# ISS_TCTRL register map
Vendor: Texas Instruments
Peripheral module from a debugger description file (folder omap5430_ES2_PUBLIC).
Registers are 32-bit, access per field, reset 0x0 unless marked. A register's access mark holds for its fields unless they carry their own. Offsets are as the file gives them; lines under a group give offsets from that group; [hi:lo] are bit positions; {n}, {i} and the like mark numbered series; 'fields as' and 'values as' point back to an identical list; <NAME> marks a mode.

## ISS_TCTRL
0x00 TCTRL_REVISION ro reset not defined — IP Revision Identifier (X.Y.R) Used by software to track features, bugs, and compatibility
  [31:0] REVISION — IP revision
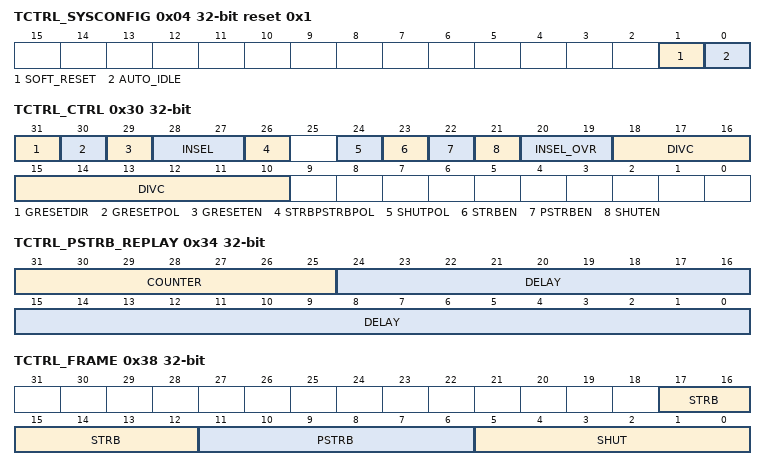
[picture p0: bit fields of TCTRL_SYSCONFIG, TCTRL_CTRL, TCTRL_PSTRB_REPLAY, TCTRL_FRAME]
0x04 TCTRL_SYSCONFIG reset 0x1 — OCP-SOCKET SYSTEM CONFIGURATION REGISTER
  [1] SOFT_RESET rw — Software reset. Set the bit to 1 to trigger the module reset. The bit is automatically reset be the hardware. During reads return 0.
    0=Normal mode; 1=Reset (The module is reset.)
  [0] AUTO_IDLE rw — Internal OCP and functional clock gating strategy
    0=Free (OCP and functional clocks are free-running); 1=Gated (Automatic clock gating strategy is applied, based on the OCP interface activity for interface clock and on the functional activity for functional clocks.)
0x08 TCTRL_SYSSTATUS ro — OCP-SOCKET SYSTEM STATUS REGISTER
  [0] RESET_DONE — Internal reset monitoring
    1=Completed (Reset completed.); 0=Ongoing (Internal module reset is ongoing.)
0x10 TCTRL_STRB_LENGTH — TIMING CONTROL - STROBE LENGTH REGISTER This register is used by the TIMING CTRL module to generate the STROBE signal.
  [23:0] LENGTH rw — Sets the length of the CAM_STROBE signal assertion in cycles of the CNTCLK clock. The CNTCLK frequency is generated with theTCTRL_CTRL[18:10] DIVC bit field. After signal assertion, the TCTRL_CTRL.STRBEN bit is automatically cleared. The possible values are 0 to 2-1 cycles.
0x14 TCTRL_PSTRB_LENGTH — TIMING CONTROL - PRESTROBE LENGTH REGISTER This register is used by the TIMING CTRL module to generate the PRESTROBE signal.
  [23:0] LENGTH rw — Sets the length of the CAM_PRESTROBE signal assertion in cycles of the CNTCLK clock. The CNTCLK frequency is generated with theTCTRL_CTRL.DIVC bit field. After signal assertion, the TCTRL_CTRL[22] PSTRBEN bit is automatically cleared. The possible values are 0 to 2-1 cycles.
0x18 TCTRL_SHUT_LENGTH — TIMING CONTROL - SHUTTER LENGTH REGISTER This register is used by the TIMING CTRL module to generate the CAM_SHUTTER signal.
  [23:0] LENGTH rw — Sets the length of the CAM_SHUTTER signal assertion in cycles of the CNTCLK clock. The CNTCLK frequency is generated with theTCTRL_CTRL.DIVC bit field. After signal assertion, the TCTRL_CTRL.SHUTEN bit is automatically cleared. The possible values are 0 to 2-1 cycles.
0x1C TCTRL_GRESET_LENGTH — TIMING CONTROL - GLOBAL SHUTTER LENGTH REGISTER This register is used by the TIMING CTRL module to generate the CAM_GLOBALRESET signal.
  [23:0] LENGTH rw — Sets the length of the CAM_GLOBALRESET signal assertion in cycles of the CNTCLK clock. The CNTCLK frequency is generated with the TCTRL_CTRL.DIVC bit field. After signal assertion, the TCTRL_CTRL.GRESETEN bit is automatically cleared. The possible values are 0 to 2-1 cycles. The polarity of the CAM_GLOBALRESET signal is set by the TCTRL_CTRL.GRESETPOL bit.
0x20 TCTRL_STRB_DELAY — TIMING CONTROL - STROBE DELAY REGISTER This register is used by the TIMING CTRL module to generate the STROBE signal.
  [24:0] DELAY rw — Sets the delay for the CAM_STROBE signal assertion in cycles of the CNTCLK clock. The CNTCLK frequency is generated with theTCTRL_CTRL.DIVC bit field. The possible values are 0 to 2-1 cycles.
0x24 TCTRL_PSTRB_DELAY — TIMING CONTROL - PRE STROBE DELAY REGISTER This register is used by the TIMING CTRL module to generate the PRESTROBE signal.
  [24:0] DELAY rw — Sets the delay for the PRESTROBE signal assertion in cycles of the CNTCLK clock. The CNTCLK frequency is generated with theTCTRL_CTRL.DIVC bit field. The possible values are 0 to 2-1 cycles.
0x28 TCTRL_SHUT_DELAY — TIMING CONTROL - SHUTTER DELAY REGISTER This register is used by the TIMING CTRL module to generate the CAM_SHUTTER signal.
  [24:0] DELAY rw — Sets the delay for the CAM_SHUTTER signal assertion in cycles of the CNTCLK clock. The CNTCLK frequency is generated with theTCTRL_CTRL.DIVC bit field. The possible values are 0 to 2-1 cycles.
0x30 TCTRL_CTRL — TIMING CONTROL - CONTROL REGISTER
  [31] GRESETDIR rw — Sets the direction of the CAM_GLOBAL_RESET signal. 0x0: INPUT – CAM_GLOBALRESET is an input to the TIMING CONTROL module. The CAM_GLOBALRESET is externally generated. 0x1: OUTPUT – CAM_GLOBALRESET is an output of the TIMING CONTROL module. CAM_GLOBALRESET is internally generated. If GRESETEN is set to 1, the internally generated CAM_GLOBALRESET will trigger the generation of the PRESTROBE, STROBE and SHUTTER signals. The frame counters are ignored.
  [30] GRESETPOL rw — Sets the polarity of the global reset signal: CAM_GLOBALRESET. It applies whatever the direction of the CAM_GLOBALRESET signal: input or output. 0x0: active high 0x1: active low
  [29] GRESETEN rw — Triggers the generation of the CAM_GLOBALRESET signal. The signal is asserted immediately. If enabled, the CAM_GLOBALRESET signal will be asserted forTCTRL_GRESET_LENGTH cycles. After the signal assertion, the enable bit is automatically cleared to 0. The polarity of the CAM_GLOBALRESET signal is set with TCTRL_CTRL.GRESETPOL. Enabling this bit triggers the generation of the CAM_SHUTTER and CAM_STROBE signals (if previously enabled). The frame counters must be set to 0 when this bit is set to 1 and GRESETDIR is set a OUTPUT.
  [28:27] INSEL rw — Sets the mode that will trigger the SHUTTER, PRESTROBE and STROBE signals.
    0=CAMEVT0 (Synchronization event from camera 0); 1=CAMEVT1 (Synchronization event from camera 1); 2=GRESET (Synchronization event from camera 2 (serial interfaces muxed with the camera Parallel interface (CPI))); 3=CAMEVT2 (GRESET – The CAM_GLOBALRESET input signal will trigger the SHUTTER, PRESTROBE and STROBE signals. In this mode, there are no frame counters. The delay counters start decrementing as soon as the CAM_GLOBALRESET signal is asserted. The polarity of the CAM_GLOBALRESET signal is set with .GRESETPOL.)
  [26] STRBPSTRBPOL rw — Sets the polarity of the strobe and prestrobe signals.
    0=High (Active high); 1=Low (Active low)
  [24] SHUTPOL rw — Sets the polarity of the mechanical shutter signal: CAM_SHUTTER
    0=High (Active high); 1=Low (Active low)
  [23] STRBEN rw — Flash strobe signal enable. If enabled, the STROBE signal will be asserted afterTCTRL_FRAME.STRB frames have been received and a delay of TCTRL_STRB_DELAY cycles have passed. The STROBE signal is asserted for TCTRL_STRB_LENGTH cycles. After the signal assertion, the enable bit is automatically cleared to 0. This signal must not be disabled by software.
  [22] PSTRBEN rw — Flash prestrobe signal enable. If enabled, the PRESTROBE signal will be asserted afterTCTRL_FRAME.PSTRB frames have been received and a delay of TCTRL_PSTRB_DELAY cycles have passed. The PRESTROBE signal is asserted for TCTRL_PSTRB_LENGTH cycles. After the signal assertion, the enable bit is automatically cleared to 0. This signal must not be disabled by software.
  [21] SHUTEN rw — Mechanical shutter signal enable. If enabled, the SHUTTER signal will be asserted afterTCTRL_FRAME.SHUT frames have been received and a delay of TCTRL_SHUT_DELAY cycles have passed. The SHUTTER signal is asserted for TCTRL_SHUT_LENGTH cycles. After the signal assertion, the enable bit is automatically cleared to 0. This signal must not be disabled by software.
  [20:19] INSEL_OVR rw — Sets the mode that will trigger the SHUTTER, PRESTROBE and STROBE signals.
    0=INSEL (Use settings defined in INSEL); 1=CAMEVT3 (Synchronization event from camera 3); 2=CAMEVT4 (Reserved)
  [18:10] DIVC rw — Sets the clock divisor value for the CNTCLK clock generation based on the CLK input clock. CNTCLK is an internal clock used by the TIMING CTRL module counters. Usually, CNTCLK = ISS_MAIN_FCLK / DIVC, except for some particular values shown hereafter.
    0=No clock. CNTCLK is gated.
0x34 TCTRL_PSTRB_REPLAY rw — TIMING CONTROL - PRESTROBE REPLAY REGISTER This register is used by the TIMING CTRL module to generate the prestrobe signal.
  [31:25] COUNTER — Sets the number of PRESTROBE pulses after the original pulse. If this bit is set to 0, the PRESTROBE signal behavior is only controlled by TCTRL_FRAME.STRB, TCTRL_PSTRB_DELAY, and TCTRL_PSTRB_LENGTH. If TCTRL_PSTRB_LENGTH=0, there is no replay. This bit is useful when one wants to enable red-eye removal.
  [24:0] DELAY — Sets the delay for the PRESTROBE signal reassertion in cycles of the CNTCLK clock. The CNTCLK frequency is generated with theTCTRL_CTRL.DIVC bit field. The possible values are 0 to 2-1 cycles. If TCTRL_PSTRB_LENGTH=0, there is no replay. This bit field must not be set to 0 if the COUNTER is set to a value different of 0. This bit is useful when one wants to enable red-eye removal.
0x38 TCTRL_FRAME — TIMING CONTROL - FRAME REGISTER This register is used by the TIMING CTRL module to generate the SHUTTER, PRESTROBE, and STROBE signals.
  [17:12] STRB rw — Frame counter for the STROBE signal generation. From 0 to 63 frames. This bit field is ignored if TCTRL.INSEL=GRESET and TCTRL_CTRL.INSEL_OVR=0
  [11:6] PSTRB rw — Frame counter for the PRESTROBE signal generation. From 0 to 63 frames. This bit field is ignored if TCTRL.INSEL=GRESET and TCTRL_CTRL.INSEL_OVR=0
  [5:0] SHUT rw — Frame counter for the SHUTTER signal generation. From 0 to 63 frames. This bit field is ignored if TCTRL.INSEL=GRESET and TCTRL_CTRL.INSEL_OVR=0
